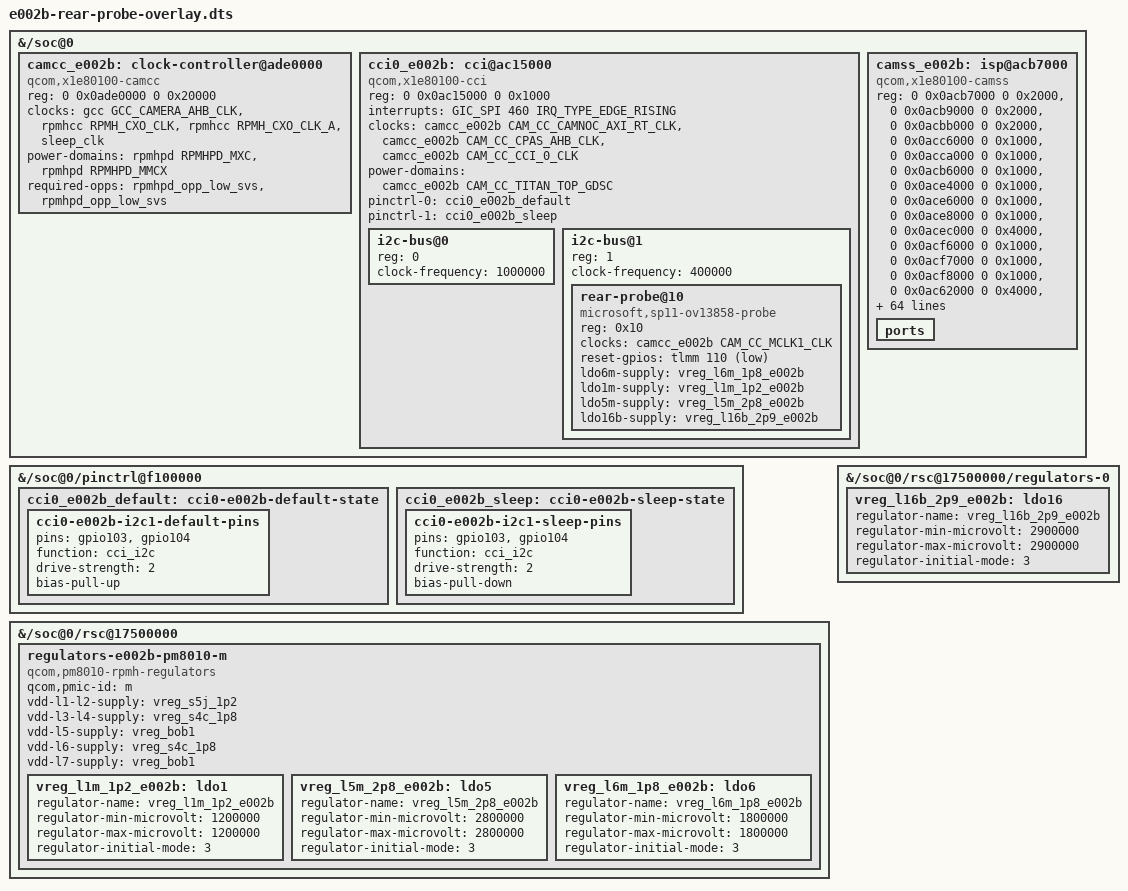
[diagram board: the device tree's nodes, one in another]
/dts-v1/;
/plugin/;

#include <dt-bindings/interrupt-controller/arm-gic.h>
#include <dt-bindings/interrupt-controller/irq.h>
#include <dt-bindings/clock/qcom,rpmh.h>
#include <dt-bindings/clock/qcom,x1e80100-gcc.h>
#include <dt-bindings/clock/qcom,x1e80100-camcc.h>
#include <dt-bindings/interconnect/qcom,icc.h>
#include <dt-bindings/interconnect/qcom,x1e80100-rpmh.h>
#include <dt-bindings/power/qcom,rpmhpd.h>
#include <dt-bindings/gpio/gpio.h>

/ {
	fragment@0 {
		target-path = "/soc@0";

		__overlay__ {
			camcc_e002b: clock-controller@ade0000 {
				compatible = "qcom,x1e80100-camcc";
				reg = <0 0x0ade0000 0 0x20000>;
				clocks = <&gcc GCC_CAMERA_AHB_CLK>,
					 <&rpmhcc RPMH_CXO_CLK>,
					 <&rpmhcc RPMH_CXO_CLK_A>,
					 <&sleep_clk>;
				power-domains = <&rpmhpd RPMHPD_MXC>,
						<&rpmhpd RPMHPD_MMCX>;
				required-opps = <&rpmhpd_opp_low_svs>,
						<&rpmhpd_opp_low_svs>;
				#clock-cells = <1>;
				#reset-cells = <1>;
				#power-domain-cells = <1>;
				status = "okay";
			};

			cci0_e002b: cci@ac15000 {
				compatible = "qcom,x1e80100-cci", "qcom,msm8996-cci";
				reg = <0 0x0ac15000 0 0x1000>;
				interrupts = <GIC_SPI 460 IRQ_TYPE_EDGE_RISING>;
				clocks = <&camcc_e002b CAM_CC_CAMNOC_AXI_RT_CLK>,
					 <&camcc_e002b CAM_CC_CPAS_AHB_CLK>,
					 <&camcc_e002b CAM_CC_CCI_0_CLK>;
				clock-names = "camnoc_axi", "cpas_ahb", "cci";
				power-domains = <&camcc_e002b CAM_CC_TITAN_TOP_GDSC>;
				pinctrl-0 = <&cci0_e002b_default>;
				pinctrl-1 = <&cci0_e002b_sleep>;
				pinctrl-names = "default", "sleep";
				#address-cells = <1>;
				#size-cells = <0>;
				status = "okay";

				i2c-bus@0 {
					reg = <0>;
					clock-frequency = <1000000>;
					#address-cells = <1>;
					#size-cells = <0>;
				};

				i2c-bus@1 {
					reg = <1>;
					clock-frequency = <400000>;
					#address-cells = <1>;
					#size-cells = <0>;

					rear-probe@10 {
						compatible = "microsoft,sp11-ov13858-probe";
						reg = <0x10>;
						clocks = <&camcc_e002b CAM_CC_MCLK1_CLK>;
						clock-names = "xclk";
						reset-gpios = <&tlmm 110 GPIO_ACTIVE_LOW>;
						ldo6m-supply = <&vreg_l6m_1p8_e002b>;
						ldo1m-supply = <&vreg_l1m_1p2_e002b>;
						ldo5m-supply = <&vreg_l5m_2p8_e002b>;
						ldo16b-supply = <&vreg_l16b_2p9_e002b>;
					};
				};
			};

			camss_e002b: isp@acb7000 {
				compatible = "qcom,x1e80100-camss";
				reg = <0 0x0acb7000 0 0x2000>,
				      <0 0x0acb9000 0 0x2000>,
				      <0 0x0acbb000 0 0x2000>,
				      <0 0x0acc6000 0 0x1000>,
				      <0 0x0acca000 0 0x1000>,
				      <0 0x0acb6000 0 0x1000>,
				      <0 0x0ace4000 0 0x1000>,
				      <0 0x0ace6000 0 0x1000>,
				      <0 0x0ace8000 0 0x1000>,
				      <0 0x0acec000 0 0x4000>,
				      <0 0x0acf6000 0 0x1000>,
				      <0 0x0acf7000 0 0x1000>,
				      <0 0x0acf8000 0 0x1000>,
				      <0 0x0ac62000 0 0x4000>,
				      <0 0x0ac71000 0 0x4000>,
				      <0 0x0acc7000 0 0x2000>,
				      <0 0x0accb000 0 0x2000>;
				reg-names = "csid0", "csid1", "csid2", "csid_lite0", "csid_lite1",
					    "csid_wrapper", "csiphy0", "csiphy1", "csiphy2", "csiphy4",
					    "csitpg0", "csitpg1", "csitpg2", "vfe0", "vfe1", "vfe_lite0", "vfe_lite1";

				clocks = <&camcc_e002b CAM_CC_CAMNOC_AXI_NRT_CLK>,
					 <&camcc_e002b CAM_CC_CAMNOC_AXI_RT_CLK>,
					 <&camcc_e002b CAM_CC_CORE_AHB_CLK>,
					 <&camcc_e002b CAM_CC_CPAS_AHB_CLK>,
					 <&camcc_e002b CAM_CC_CPAS_FAST_AHB_CLK>,
					 <&camcc_e002b CAM_CC_CPAS_IFE_0_CLK>,
					 <&camcc_e002b CAM_CC_CPAS_IFE_1_CLK>,
					 <&camcc_e002b CAM_CC_CPAS_IFE_LITE_CLK>,
					 <&camcc_e002b CAM_CC_CPHY_RX_CLK_SRC>,
					 <&camcc_e002b CAM_CC_CSID_CLK>,
					 <&camcc_e002b CAM_CC_CSID_CSIPHY_RX_CLK>,
					 <&camcc_e002b CAM_CC_CSIPHY0_CLK>,
					 <&camcc_e002b CAM_CC_CSI0PHYTIMER_CLK>,
					 <&camcc_e002b CAM_CC_CSIPHY1_CLK>,
					 <&camcc_e002b CAM_CC_CSI1PHYTIMER_CLK>,
					 <&camcc_e002b CAM_CC_CSIPHY2_CLK>,
					 <&camcc_e002b CAM_CC_CSI2PHYTIMER_CLK>,
					 <&camcc_e002b CAM_CC_CSIPHY4_CLK>,
					 <&camcc_e002b CAM_CC_CSI4PHYTIMER_CLK>,
					 <&gcc GCC_CAMERA_HF_AXI_CLK>,
					 <&gcc GCC_CAMERA_SF_AXI_CLK>,
					 <&camcc_e002b CAM_CC_IFE_0_CLK>,
					 <&camcc_e002b CAM_CC_IFE_0_FAST_AHB_CLK>,
					 <&camcc_e002b CAM_CC_IFE_1_CLK>,
					 <&camcc_e002b CAM_CC_IFE_1_FAST_AHB_CLK>,
					 <&camcc_e002b CAM_CC_IFE_LITE_CLK>,
					 <&camcc_e002b CAM_CC_IFE_LITE_AHB_CLK>,
					 <&camcc_e002b CAM_CC_IFE_LITE_CPHY_RX_CLK>,
					 <&camcc_e002b CAM_CC_IFE_LITE_CSID_CLK>;
				clock-names = "camnoc_nrt_axi", "camnoc_rt_axi", "core_ahb", "cpas_ahb",
					      "cpas_fast_ahb", "cpas_vfe0", "cpas_vfe1", "cpas_vfe_lite",
					      "cphy_rx_clk_src", "csid", "csid_csiphy_rx", "csiphy0", "csiphy0_timer",
					      "csiphy1", "csiphy1_timer", "csiphy2", "csiphy2_timer", "csiphy4", "csiphy4_timer",
					      "gcc_axi_hf", "gcc_axi_sf", "vfe0", "vfe0_fast_ahb", "vfe1", "vfe1_fast_ahb",
					      "vfe_lite", "vfe_lite_ahb", "vfe_lite_cphy_rx", "vfe_lite_csid";

				interrupts = <GIC_SPI 464 IRQ_TYPE_EDGE_RISING>,
					     <GIC_SPI 466 IRQ_TYPE_EDGE_RISING>,
					     <GIC_SPI 431 IRQ_TYPE_EDGE_RISING>,
					     <GIC_SPI 468 IRQ_TYPE_EDGE_RISING>,
					     <GIC_SPI 359 IRQ_TYPE_EDGE_RISING>,
					     <GIC_SPI 477 IRQ_TYPE_EDGE_RISING>,
					     <GIC_SPI 478 IRQ_TYPE_EDGE_RISING>,
					     <GIC_SPI 479 IRQ_TYPE_EDGE_RISING>,
					     <GIC_SPI 122 IRQ_TYPE_EDGE_RISING>,
					     <GIC_SPI 465 IRQ_TYPE_EDGE_RISING>,
					     <GIC_SPI 467 IRQ_TYPE_EDGE_RISING>,
					     <GIC_SPI 469 IRQ_TYPE_EDGE_RISING>,
					     <GIC_SPI 360 IRQ_TYPE_EDGE_RISING>;
				interrupt-names = "csid0", "csid1", "csid2", "csid_lite0", "csid_lite1",
						 "csiphy0", "csiphy1", "csiphy2", "csiphy4", "vfe0", "vfe1", "vfe_lite0", "vfe_lite1";

				interconnects = <&gem_noc MASTER_APPSS_PROC QCOM_ICC_TAG_ACTIVE_ONLY
						 &config_noc SLAVE_CAMERA_CFG QCOM_ICC_TAG_ACTIVE_ONLY>,
						<&mmss_noc MASTER_CAMNOC_HF QCOM_ICC_TAG_ALWAYS
						 &mc_virt SLAVE_EBI1 QCOM_ICC_TAG_ALWAYS>,
						<&mmss_noc MASTER_CAMNOC_SF QCOM_ICC_TAG_ALWAYS
						 &mc_virt SLAVE_EBI1 QCOM_ICC_TAG_ALWAYS>,
						<&mmss_noc MASTER_CAMNOC_ICP QCOM_ICC_TAG_ALWAYS
						 &mc_virt SLAVE_EBI1 QCOM_ICC_TAG_ALWAYS>;
				interconnect-names = "ahb", "hf_mnoc", "sf_mnoc", "sf_icp_mnoc";

				iommus = <&apps_smmu 0x800 0x60>,
					 <&apps_smmu 0x860 0x60>,
					 <&apps_smmu 0x1800 0x60>,
					 <&apps_smmu 0x1860 0x60>,
					 <&apps_smmu 0x18e0 0x00>,
					 <&apps_smmu 0x1980 0x20>,
					 <&apps_smmu 0x1900 0x00>,
					 <&apps_smmu 0x19a0 0x20>;

				power-domains = <&camcc_e002b CAM_CC_IFE_0_GDSC>,
						<&camcc_e002b CAM_CC_IFE_1_GDSC>,
						<&camcc_e002b CAM_CC_TITAN_TOP_GDSC>;
				power-domain-names = "ife0", "ife1", "top";

				/* Old integrated CAMSS binding has one shared pair. For E002 rear-only,
				 * point it at the X1E CSI0/1 rails used by CSIPHY1. No PHY is enabled
				 * until a stream is started, which E002a deliberately never does. */
				vdd-csiphy-0p8-supply = <&vreg_l2c_0p8>;
				vdd-csiphy-1p2-supply = <&vreg_l1c_1p2>;

				status = "okay";

				ports {
					#address-cells = <1>;
					#size-cells = <0>;
				};
			};
		};
	};

	fragment@1 {
		target-path = "/soc@0/pinctrl@f100000";
		__overlay__ {
			cci0_e002b_default: cci0-e002b-default-state {
				cci0-e002b-i2c1-default-pins {
					pins = "gpio103", "gpio104";
					function = "cci_i2c";
					drive-strength = <2>;
					bias-pull-up;
				};
			};

			cci0_e002b_sleep: cci0-e002b-sleep-state {
				cci0-e002b-i2c1-sleep-pins {
					pins = "gpio103", "gpio104";
					function = "cci_i2c";
					drive-strength = <2>;
					bias-pull-down;
				};
			};
		};
	};

	fragment@2 {
		target-path = "/soc@0/rsc@17500000";
		__overlay__ {
			regulators-e002b-pm8010-m {
				compatible = "qcom,pm8010-rpmh-regulators";
				qcom,pmic-id = "m";
				vdd-l1-l2-supply = <&vreg_s5j_1p2>;
				vdd-l3-l4-supply = <&vreg_s4c_1p8>;
				vdd-l5-supply = <&vreg_bob1>;
				vdd-l6-supply = <&vreg_s4c_1p8>;
				vdd-l7-supply = <&vreg_bob1>;

				vreg_l1m_1p2_e002b: ldo1 {
					regulator-name = "vreg_l1m_1p2_e002b";
					regulator-min-microvolt = <1200000>;
					regulator-max-microvolt = <1200000>;
					regulator-initial-mode = <3>;
				};

				vreg_l5m_2p8_e002b: ldo5 {
					regulator-name = "vreg_l5m_2p8_e002b";
					regulator-min-microvolt = <2800000>;
					regulator-max-microvolt = <2800000>;
					regulator-initial-mode = <3>;
				};

				vreg_l6m_1p8_e002b: ldo6 {
					regulator-name = "vreg_l6m_1p8_e002b";
					regulator-min-microvolt = <1800000>;
					regulator-max-microvolt = <1800000>;
					regulator-initial-mode = <3>;
				};
			};
		};
	};

	fragment@3 {
		target-path = "/soc@0/rsc@17500000/regulators-0";
		__overlay__ {
			vreg_l16b_2p9_e002b: ldo16 {
				regulator-name = "vreg_l16b_2p9_e002b";
				regulator-min-microvolt = <2900000>;
				regulator-max-microvolt = <2900000>;
				regulator-initial-mode = <3>;
			};
		};
	};
};
